# SWM201 register map
File version: 1.0
CPU: CM0 r1p0, little endian, 2 interrupt priority bits
Registers are 32-bit, read-write, no defined reset value unless marked. A register's access mark holds for its fields unless they carry their own. Offsets are from the block's base; [hi:lo] are bit positions; lines under a group give offsets from that group; {n}, {i} and the like mark numbered series; 'fields as' and 'values as' point back to an identical list.

## PWM0 — Registers group
Base 0x40046000
Same registers: PWM1 0x40046080
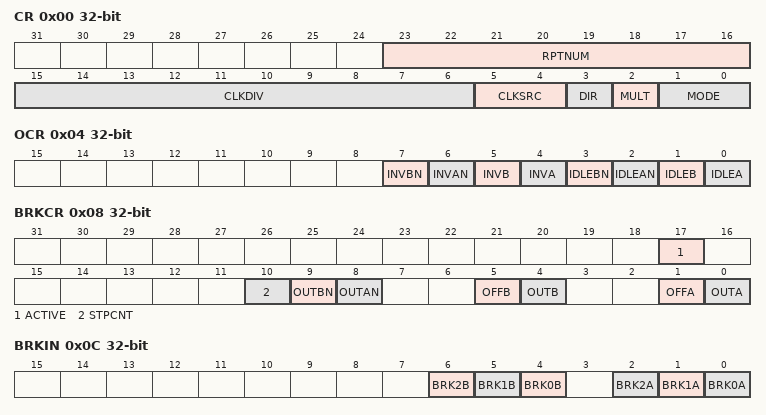
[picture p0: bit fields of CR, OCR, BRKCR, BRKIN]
0x00 CR
  [23:16] RPTNUM, [15:6] CLKDIV, [5:4] CLKSRC, [3] DIR, [2] MULT, [1:0] MODE
0x04 OCR
  [7] INVBN, [6] INVAN, [5] INVB, [4] INVA, [3] IDLEBN, [2] IDLEAN, [1] IDLEB, [0] IDLEA
0x08 BRKCR
  [17] ACTIVE, [10] STPCNT, [9] OUTBN, [8] OUTAN, [5] OFFB, [4] OUTB, [1] OFFA, [0] OUTA
0x0C BRKIN
  [6] BRK2B, [5] BRK1B, [4] BRK0B, [2] BRK2A, [1] BRK1A, [0] BRK0A
0x20 PERIOD
0x24 CMPA
0x28 CMPB
0x2C DZA
0x30 DZB
0x34 CMPA2
0x38 CMPB2
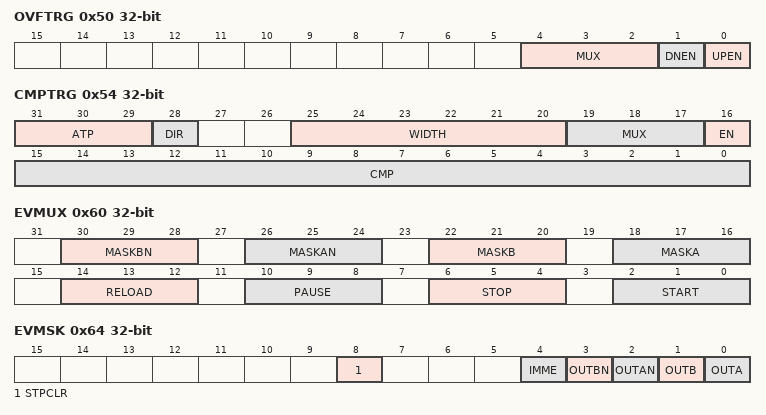
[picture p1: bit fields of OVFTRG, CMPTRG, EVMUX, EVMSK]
0x50 OVFTRG
  [4:2] MUX, [1] DNEN, [0] UPEN
0x54 CMPTRG
  [31:29] ATP, [28] DIR, [25:20] WIDTH, [19:17] MUX, [16] EN, [15:0] CMP
0x58 CMPTRG2
  [2:0] INTV
0x60 EVMUX
  [30:28] MASKBN, [26:24] MASKAN, [22:20] MASKB, [18:16] MASKA, [14:12] RELOAD, [10:8] PAUSE, [6:4] STOP, [2:0] START
0x64 EVMSK
  [8] STPCLR, [4] IMME, [3] OUTBN, [2] OUTAN, [1] OUTB, [0] OUTA
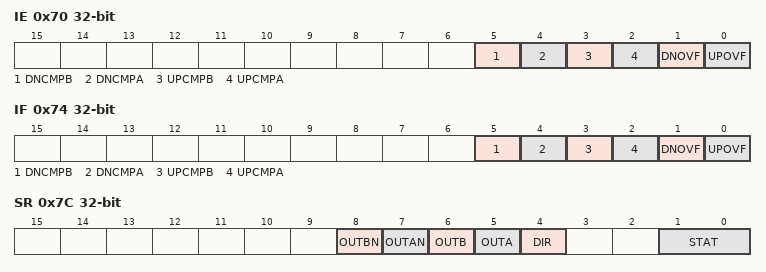
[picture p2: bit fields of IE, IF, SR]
0x70 IE
  [5] DNCMPB, [4] DNCMPA, [3] UPCMPB, [2] UPCMPA, [1] DNOVF, [0] UPOVF
0x74 IF
  [5] DNCMPB, [4] DNCMPA, [3] UPCMPB, [2] UPCMPA, [1] DNOVF, [0] UPOVF
0x78 VALUE
0x7C SR
  [8] OUTBN, [7] OUTAN, [6] OUTB, [5] OUTA, [4] DIR, [1:0] STAT

## PWMG — Registers group
Base 0x40046400
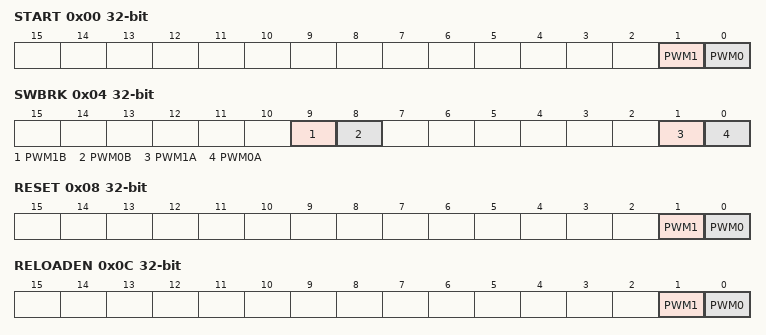
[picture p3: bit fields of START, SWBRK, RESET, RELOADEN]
0x00 START
  [1] PWM1, [0] PWM0
0x04 SWBRK
  [9] PWM1B, [8] PWM0B, [1] PWM1A, [0] PWM0A
0x08 RESET
  [1] PWM1, [0] PWM0
0x0C RELOADEN
  [1] PWM1, [0] PWM0
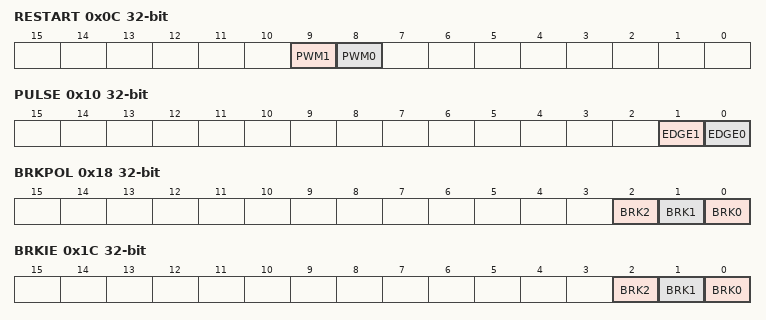
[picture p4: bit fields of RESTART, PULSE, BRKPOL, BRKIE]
0x0C RESTART (alternate view of RELOADEN)
  [9] PWM1, [8] PWM0
0x10 PULSE
  [1] EDGE1, [0] EDGE0
0x14 FILTER
0x18 BRKPOL
  [2] BRK2, [1] BRK1, [0] BRK0
0x1C BRKIE
  [2] BRK2, [1] BRK1, [0] BRK0
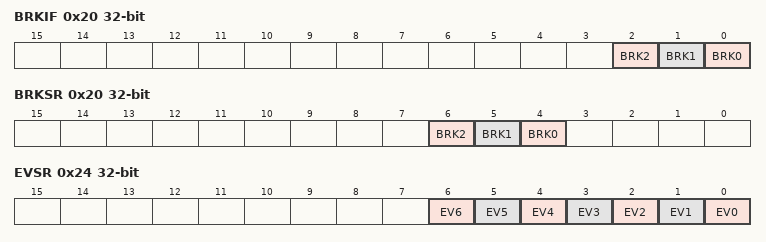
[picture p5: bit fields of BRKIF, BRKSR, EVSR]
0x20 BRKIF
  [2] BRK2, [1] BRK1, [0] BRK0
0x20 BRKSR (alternate view of BRKIF)
  [6] BRK2, [5] BRK1, [4] BRK0
0x24 EVSR
  [n] EV{n} (n=0..6)

## CORDIC — Registers group
Base 0x40003000
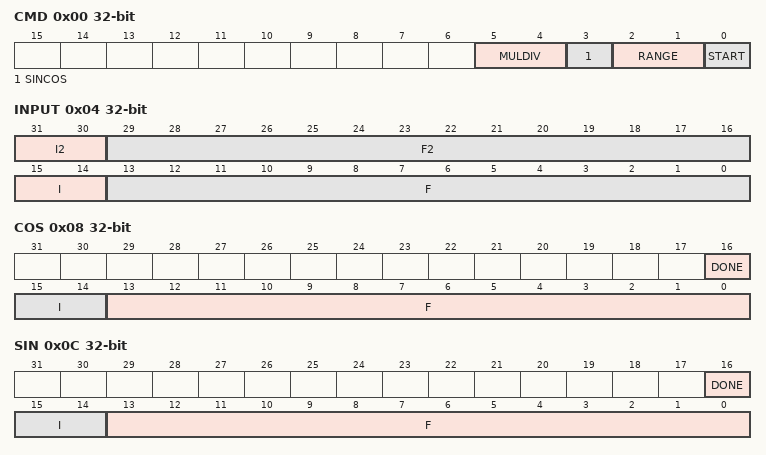
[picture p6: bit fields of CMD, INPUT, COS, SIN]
0x00 CMD
  [5:4] MULDIV, [3] SINCOS, [2:1] RANGE, [0] START
0x04 INPUT
  [31:30] I2, [29:16] F2, [15:14] I, [13:0] F
0x08 COS
  [16] DONE, [15:14] I, [13:0] F
0x0C SIN
  [16] DONE, [15:14] I, [13:0] F
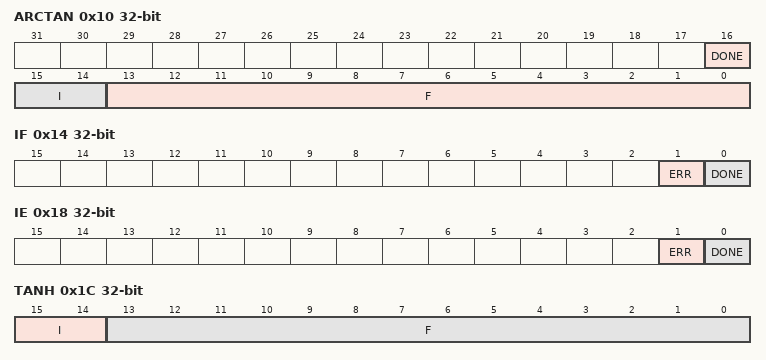
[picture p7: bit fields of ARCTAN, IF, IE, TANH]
0x10 ARCTAN
  [16] DONE, [15:14] I, [13:0] F
0x14 IF
  [1] ERR, [0] DONE
0x18 IE
  [1] ERR, [0] DONE
0x1C TANH
  [15:14] I, [13:0] F

## DIV — Registers group
Base 0x40003800
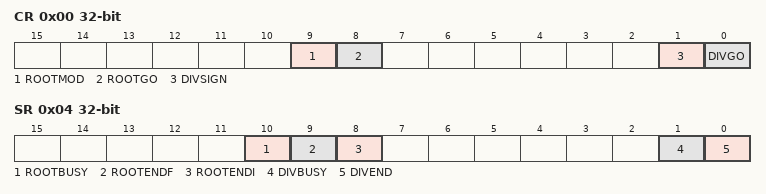
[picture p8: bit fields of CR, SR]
0x00 CR
  [9] ROOTMOD, [8] ROOTGO, [1] DIVSIGN, [0] DIVGO
0x04 SR
  [10] ROOTBUSY, [9] ROOTENDF, [8] ROOTENDI, [1] DIVBUSY, [0] DIVEND
0x10 DIVIDEND
0x14 DIVISOR
0x18 QUO
0x1C REMAIN
0x20 RADICAND
0x24 ROOT

## FMC — Registers group
Base 0x4004A000
0x00 DATA
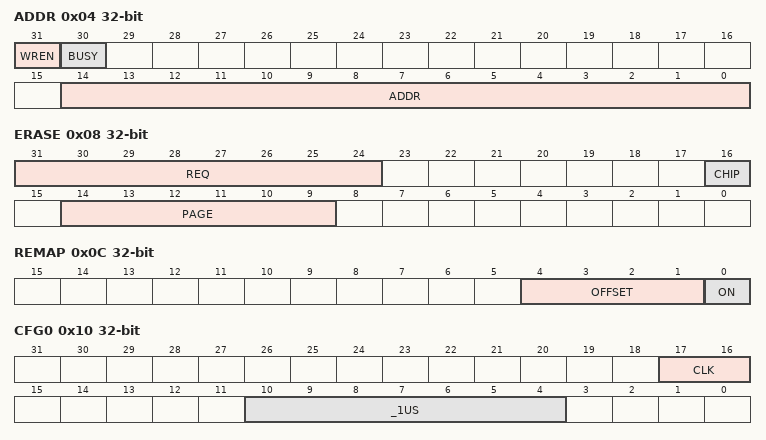
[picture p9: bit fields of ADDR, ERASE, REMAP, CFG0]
0x04 ADDR
  [31] WREN, [30] BUSY, [14:0] ADDR
0x08 ERASE
  [31:24] REQ, [16] CHIP, [14:9] PAGE
0x0C REMAP
  [4:1] OFFSET, [0] ON
0x10 CFG0
  [17:16] CLK, [10:4] _1US
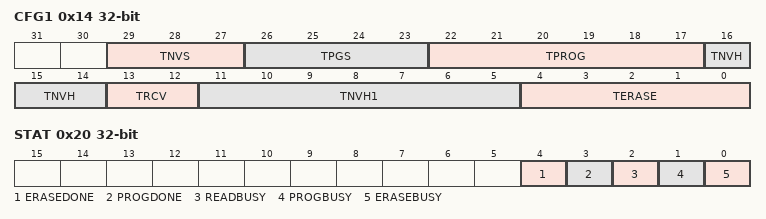
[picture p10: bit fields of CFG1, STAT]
0x14 CFG1
  [29:27] TNVS, [26:23] TPGS, [22:17] TPROG, [16:14] TNVH, [13:12] TRCV, [11:5] TNVH1, [4:0] TERASE
0x18 CFG2
0x20 STAT
  [4] ERASEDONE, [3] PROGDONE, [2] READBUSY, [1] PROGBUSY, [0] ERASEBUSY

## RTC — Registers group
Base 0x4004B800
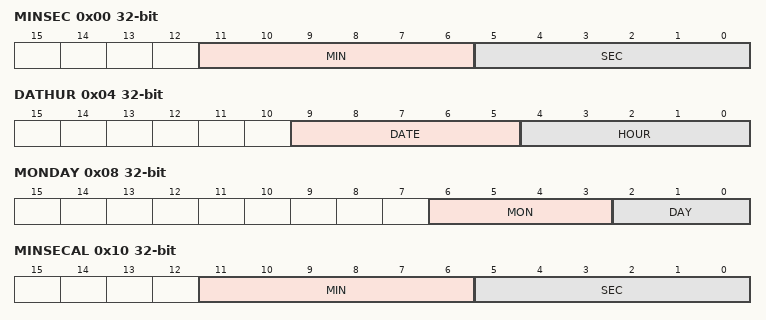
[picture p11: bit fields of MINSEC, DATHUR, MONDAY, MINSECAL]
0x00 MINSEC
  [11:6] MIN, [5:0] SEC
0x04 DATHUR
  [9:5] DATE, [4:0] HOUR
0x08 MONDAY
  [6:3] MON, [2:0] DAY
0x0C YEAR
0x10 MINSECAL
  [11:6] MIN, [5:0] SEC
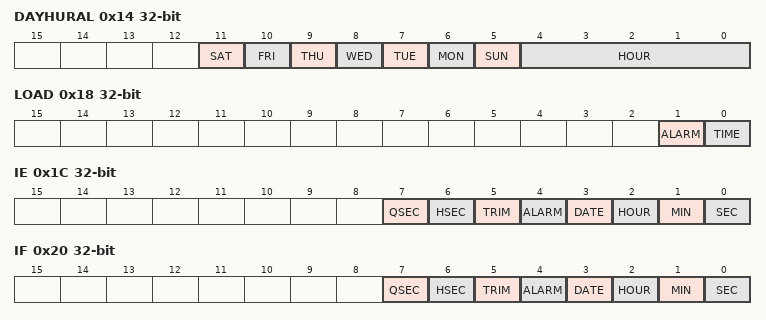
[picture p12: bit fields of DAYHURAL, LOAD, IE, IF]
0x14 DAYHURAL
  [11] SAT, [10] FRI, [9] THU, [8] WED, [7] TUE, [6] MON, [5] SUN, [4:0] HOUR
0x18 LOAD
  [1] ALARM, [0] TIME
0x1C IE
  [7] QSEC, [6] HSEC, [5] TRIM, [4] ALARM, [3] DATE, [2] HOUR, [1] MIN, [0] SEC
0x20 IF
  fields as IE
0x24 EN
0x28 CFGABLE
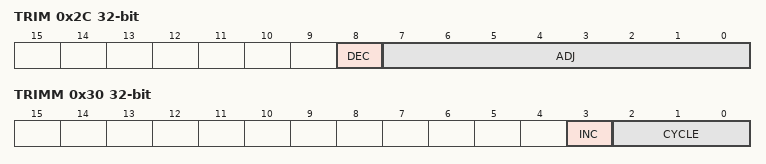
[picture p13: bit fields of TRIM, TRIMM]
0x2C TRIM
  [8] DEC, [7:0] ADJ
0x30 TRIMM
  [3] INC, [2:0] CYCLE

## WDT — Registers group
Base 0x400A0800
0x00 RSTVAL
0x04 INTVAL
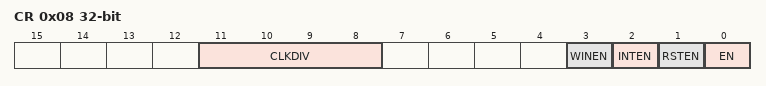
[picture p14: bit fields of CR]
0x08 CR
  [11:8] CLKDIV, [3] WINEN, [2] INTEN, [1] RSTEN, [0] EN
0x0C IF
0x10 FEED

## QEI — Registers group
Base 0x4004D800
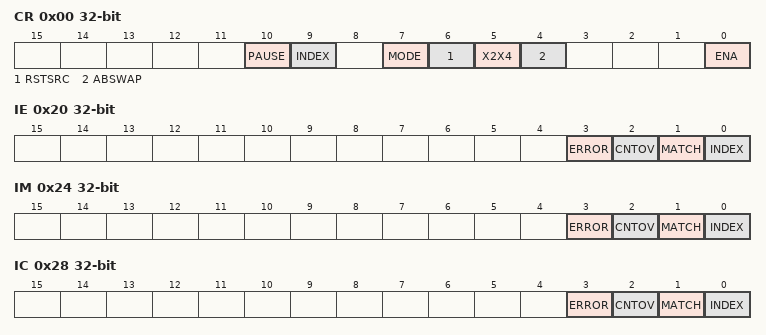
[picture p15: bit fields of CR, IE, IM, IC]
0x00 CR
  [10] PAUSE, [9] INDEX, [7] MODE, [6] RSTSRC, [5] X2X4, [4] ABSWAP, [0] ENA
0x04 POSCNT
0x08 MAXCNT
0x20 IE
  [3] ERROR, [2] CNTOV, [1] MATCH, [0] INDEX
0x24 IM
  [3] ERROR, [2] CNTOV, [1] MATCH, [0] INDEX
0x28 IC wo
  [3] ERROR, [2] CNTOV, [1] MATCH, [0] INDEX
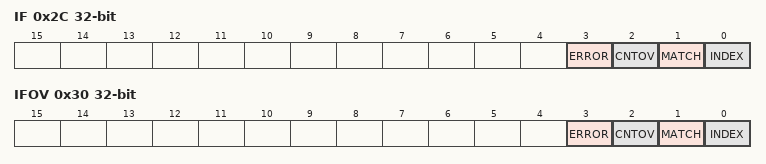
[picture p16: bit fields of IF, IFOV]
0x2C IF ro
  [3] ERROR, [2] CNTOV, [1] MATCH, [0] INDEX
0x30 IFOV
  [3] ERROR, [2] CNTOV, [1] MATCH, [0] INDEX
